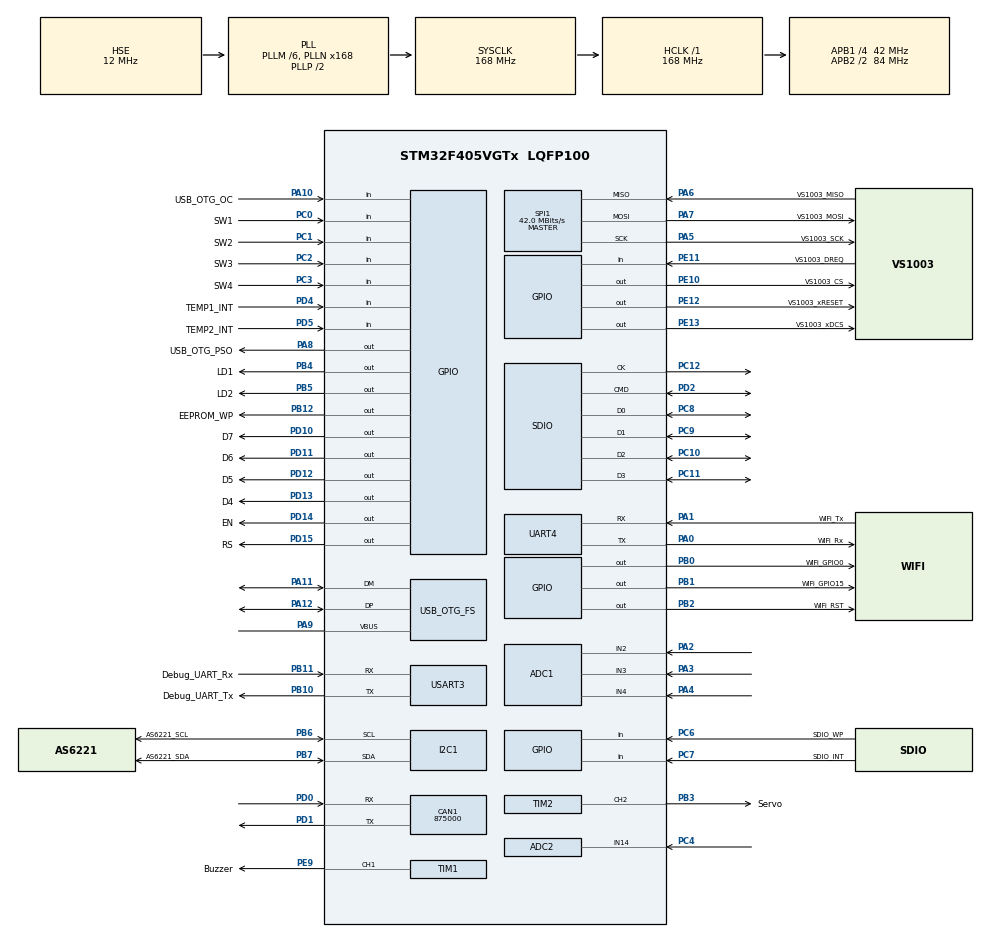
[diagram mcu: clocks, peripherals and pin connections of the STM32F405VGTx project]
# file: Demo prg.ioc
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ADC1.Channel-0\#ChannelRegularConversion=ADC_CHANNEL_2
ADC1.Channel-1\#ChannelRegularConversion=ADC_CHANNEL_3
ADC1.Channel-2\#ChannelRegularConversion=ADC_CHANNEL_4
ADC1.ClockPrescaler=ADC_CLOCK_SYNC_PCLK_DIV4
ADC1.ContinuousConvMode=ENABLE
ADC1.DMAContinuousRequests=ENABLE
ADC1.NbrOfConversion=3
ADC1.NbrOfConversionFlag=1
ADC1.Rank-0\#ChannelRegularConversion=1
ADC1.Rank-1\#ChannelRegularConversion=2
ADC1.Rank-2\#ChannelRegularConversion=3
ADC1.SamplingTime-0\#ChannelRegularConversion=ADC_SAMPLETIME_84CYCLES
ADC1.SamplingTime-1\#ChannelRegularConversion=ADC_SAMPLETIME_84CYCLES
ADC1.SamplingTime-2\#ChannelRegularConversion=ADC_SAMPLETIME_84CYCLES
ADC1.ScanConvMode=ENABLE
ADC1.master=1
ADC2.Channel-0\#ChannelRegularConversion=ADC_CHANNEL_14
ADC2.ClockPrescaler=ADC_CLOCK_SYNC_PCLK_DIV4
ADC2.ContinuousConvMode=ENABLE
ADC2.NbrOfConversionFlag=1
ADC2.Rank-0\#ChannelRegularConversion=1
ADC2.SamplingTime-0\#ChannelRegularConversion=ADC_SAMPLETIME_84CYCLES
ADC2.ScanConvMode=ENABLE
CAN1.CalculateBaudRate=875000
CAN1.CalculateTimeBit=1142
CAN1.CalculateTimeQuantum=380.95238095238096
Dma.ADC1.0.Direction=DMA_PERIPH_TO_MEMORY
Dma.ADC1.0.FIFOMode=DMA_FIFOMODE_DISABLE
Dma.ADC1.0.Instance=DMA2_Stream0
Dma.ADC1.0.MemDataAlignment=DMA_MDATAALIGN_HALFWORD
Dma.ADC1.0.MemInc=DMA_MINC_ENABLE
Dma.ADC1.0.Mode=DMA_CIRCULAR
Dma.ADC1.0.PeriphDataAlignment=DMA_PDATAALIGN_HALFWORD
Dma.ADC1.0.PeriphInc=DMA_PINC_DISABLE
Dma.ADC1.0.Priority=DMA_PRIORITY_LOW
Dma.Request0=ADC1
Dma.Request1=SDIO_TX
Dma.Request2=SDIO_RX
Dma.SDIO_RX.2.Direction=DMA_PERIPH_TO_MEMORY
Dma.SDIO_RX.2.FIFOMode=DMA_FIFOMODE_ENABLE
Dma.SDIO_RX.2.FIFOThreshold=DMA_FIFO_THRESHOLD_FULL
Dma.SDIO_RX.2.Instance=DMA2_Stream6
Dma.SDIO_RX.2.MemBurst=DMA_MBURST_INC4
Dma.SDIO_RX.2.MemDataAlignment=DMA_MDATAALIGN_WORD
Dma.SDIO_RX.2.MemInc=DMA_MINC_ENABLE
Dma.SDIO_RX.2.Mode=DMA_PFCTRL
Dma.SDIO_RX.2.PeriphBurst=DMA_PBURST_INC4
Dma.SDIO_RX.2.PeriphDataAlignment=DMA_PDATAALIGN_WORD
Dma.SDIO_RX.2.PeriphInc=DMA_PINC_DISABLE
Dma.SDIO_RX.2.Priority=DMA_PRIORITY_LOW
Dma.SDIO_TX.1.Direction=DMA_MEMORY_TO_PERIPH
Dma.SDIO_TX.1.FIFOMode=DMA_FIFOMODE_ENABLE
Dma.SDIO_TX.1.FIFOThreshold=DMA_FIFO_THRESHOLD_FULL
Dma.SDIO_TX.1.Instance=DMA2_Stream3
Dma.SDIO_TX.1.MemBurst=DMA_MBURST_INC4
Dma.SDIO_TX.1.MemDataAlignment=DMA_MDATAALIGN_WORD
Dma.SDIO_TX.1.MemInc=DMA_MINC_ENABLE
Dma.SDIO_TX.1.Mode=DMA_PFCTRL
Dma.SDIO_TX.1.PeriphBurst=DMA_PBURST_INC4
Dma.SDIO_TX.1.PeriphDataAlignment=DMA_PDATAALIGN_WORD
Dma.SDIO_TX.1.PeriphInc=DMA_PINC_DISABLE
Dma.SDIO_TX.1.Priority=DMA_PRIORITY_LOW
FATFS.USE_DMA_CODE_SD=1
FATFS._USE_LFN=1
I2C1.I2C_Mode=I2C_Fast
Mcu.Family=STM32F4
Mcu.Name=STM32F405VGTx
Mcu.Package=LQFP100
NVIC.DMA2_Stream0_IRQn=true\:0\:0\:false\:false\:true\:false\:true\:true
NVIC.DMA2_Stream3_IRQn=true\:0\:0\:false\:false\:true\:false\:true\:true
NVIC.DMA2_Stream6_IRQn=true\:0\:0\:false\:false\:true\:false\:true\:true
NVIC.PriorityGroup=NVIC_PRIORITYGROUP_4
NVIC.SDIO_IRQn=true\:0\:0\:false\:false\:true\:true\:true\:true
PA0-WKUP.GPIO_Label=WiFi_Rx
PA0-WKUP.Mode=Asynchronous
PA0-WKUP.Signal=UART4_TX
PA1.GPIO_Label=WiFi_Tx
PA1.Mode=Asynchronous
PA1.Signal=UART4_RX
PA10.GPIO_Label=USB_OTG_OC
PA10.Signal=GPIO_Input
PA11.Mode=Host_Only
PA11.Signal=USB_OTG_FS_DM
PA12.Mode=Host_Only
PA12.Signal=USB_OTG_FS_DP
PA2.Signal=ADCx_IN2
PA3.Signal=ADCx_IN3
PA4.Signal=ADCx_IN4
PA5.GPIO_Label=VS1003_SCK
PA5.Mode=Full_Duplex_Master
PA5.Signal=SPI1_SCK
PA6.GPIO_Label=VS1003_MISO
PA6.Mode=Full_Duplex_Master
PA6.Signal=SPI1_MISO
PA7.GPIO_Label=VS1003_MOSI
PA7.Mode=Full_Duplex_Master
PA7.Signal=SPI1_MOSI
PA8.GPIO_Label=USB_OTG_PSO
PA8.Signal=GPIO_Output
PA9.Mode=Activate_VBUS
PA9.Signal=USB_OTG_FS_VBUS
PB0.GPIO_Label=WiFi_GPIO0
PB0.Signal=GPIO_Output
PB1.GPIO_Label=WiFi_GPIO15
PB1.Signal=GPIO_Output
PB10.GPIO_Label=Debug_UART_Tx
PB10.Mode=Asynchronous
PB10.Signal=USART3_TX
PB11.GPIO_Label=Debug_UART_Rx
PB11.Mode=Asynchronous
PB11.Signal=USART3_RX
PB12.GPIO_Label=EEPROM_WP
PB12.Signal=GPIO_Output
PB2.GPIO_Label=WiFi_RST
PB2.Signal=GPIO_Output
PB3.GPIO_Label=Servo
PB3.Signal=S_TIM2_CH2
PB4.GPIO_Label=LD1
PB4.Signal=GPIO_Output
PB5.GPIO_Label=LD2
PB5.Signal=GPIO_Output
PB6.GPIO_Label=AS6221_SCL
PB6.Mode=I2C
PB6.Signal=I2C1_SCL
PB7.GPIO_Label=AS6221_SDA
PB7.Mode=I2C
PB7.Signal=I2C1_SDA
PC0.GPIO_Label=SW1
PC0.Signal=GPIO_Input
PC1.GPIO_Label=SW2
PC1.Signal=GPIO_Input
PC10.Mode=SD_4_bits_Wide_bus
PC10.Signal=SDIO_D2
PC11.Mode=SD_4_bits_Wide_bus
PC11.Signal=SDIO_D3
PC12.Mode=SD_4_bits_Wide_bus
PC12.Signal=SDIO_CK
PC2.GPIO_Label=SW3
PC2.Signal=GPIO_Input
PC3.GPIO_Label=SW4
PC3.Signal=GPIO_Input
PC4.Signal=ADCx_IN14
PC6.GPIO_Label=SDIO_WP
PC6.Signal=GPIO_Input
PC7.GPIO_Label=SDIO_INT
PC7.Signal=GPIO_Input
PC8.Mode=SD_4_bits_Wide_bus
PC8.Signal=SDIO_D0
PC9.Mode=SD_4_bits_Wide_bus
PC9.Signal=SDIO_D1
PD0.Mode=CAN_Activate
PD0.Signal=CAN1_RX
PD1.Mode=CAN_Activate
PD1.Signal=CAN1_TX
PD10.GPIO_Label=D7
PD10.Signal=GPIO_Output
PD11.GPIO_Label=D6
PD11.Signal=GPIO_Output
PD12.GPIO_Label=D5
PD12.Signal=GPIO_Output
PD13.GPIO_Label=D4
PD13.Signal=GPIO_Output
PD14.GPIO_Label=EN
PD14.Signal=GPIO_Output
PD15.GPIO_Label=RS
PD15.Signal=GPIO_Output
PD2.Mode=SD_4_bits_Wide_bus
PD2.Signal=SDIO_CMD
PD4.GPIO_Label=TEMP1_INT
PD4.Signal=GPIO_Input
PD5.GPIO_Label=TEMP2_INT
PD5.Signal=GPIO_Input
PE10.GPIO_Label=VS1003_CS
PE10.Signal=GPIO_Output
PE11.GPIO_Label=VS1003_DREQ
PE11.Signal=GPIO_Input
PE12.GPIO_Label=VS1003_xRESET
PE12.Signal=GPIO_Output
PE13.GPIO_Label=VS1003_xDCS
PE13.Signal=GPIO_Output
PE9.GPIO_Label=Buzzer
PE9.Signal=S_TIM1_CH1
PH0-OSC_IN.Mode=HSE-External-Oscillator
PH0-OSC_IN.Signal=RCC_OSC_IN
PH1-OSC_OUT.Mode=HSE-External-Oscillator
PH1-OSC_OUT.Signal=RCC_OSC_OUT
ProjectManager.HeapSize=0x200
ProjectManager.StackSize=0x400
ProjectManager.TargetToolchain=STM32CubeIDE
RCC.48MHZClocksFreq_Value=48000000
RCC.AHBFreq_Value=168000000
RCC.APB1CLKDivider=RCC_HCLK_DIV4
RCC.APB1Freq_Value=42000000
RCC.APB1TimFreq_Value=84000000
RCC.APB2CLKDivider=RCC_HCLK_DIV2
RCC.APB2Freq_Value=84000000
RCC.APB2TimFreq_Value=168000000
RCC.CortexFreq_Value=168000000
RCC.HCLKFreq_Value=168000000
RCC.HSE_VALUE=12000000
RCC.HSI_VALUE=16000000
RCC.LSE_VALUE=32768
RCC.PLLM=6
RCC.PLLN=168
RCC.PLLQ=7
RCC.SYSCLKFreq_VALUE=168000000
RCC.SYSCLKSource=RCC_SYSCLKSOURCE_PLLCLK
RCC.VCOOutputFreq_Value=336000000
SH.ADCx_IN14.0=ADC2_IN14,IN14
SH.ADCx_IN2.0=ADC1_IN2,IN2
SH.ADCx_IN3.0=ADC1_IN3,IN3
SH.ADCx_IN4.0=ADC1_IN4,IN4
SH.S_TIM1_CH1.0=TIM1_CH1,PWM Generation1 CH1
SH.S_TIM2_CH2.0=TIM2_CH2,PWM Generation2 CH2
SPI1.CalculateBaudRate=42.0 MBits/s
SPI1.Direction=SPI_DIRECTION_2LINES
SPI1.Mode=SPI_MODE_MASTER
SPI1.VirtualType=VM_MASTER
TIM1.Channel-PWM\ Generation1\ CH1=TIM_CHANNEL_1
TIM1.Period=9
TIM1.Prescaler=8399
TIM1.Pulse-PWM\ Generation1\ CH1=5
TIM2.Channel-PWM\ Generation2\ CH2=TIM_CHANNEL_2
TIM2.Period=19999
TIM2.Prescaler=167
TIM2.Pulse-PWM\ Generation2\ CH2=1500
TIM4.Prescaler=83
UART4.VirtualMode=Asynchronous
USART3.VirtualMode=VM_ASYNC
USB_OTG_FS.VirtualMode=Host_Only
USB_OTG_FS.phy_itface=HCD_PHY_EMBEDDED
VP_FATFS_VS_SDIO.Mode=SDIO
VP_TIM1_VS_ClockSourceINT.Mode=Internal
VP_TIM2_VS_ClockSourceINT.Mode=Internal
VP_TIM4_VS_ClockSourceINT.Mode=Internal
board=custom

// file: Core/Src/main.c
/* USER CODE BEGIN Header */
/**
  ******************************************************************************
  * @file           : main.c
  * @brief          : Main program body
  ******************************************************************************
  * @attention
  *
  * Copyright (c) 2025 STMicroelectronics.
  * All rights reserved.
  *
  * This software is licensed under terms that can be found in the LICENSE file
  * in the root directory of this software component.
  * If no LICENSE file comes with this software, it is provided AS-IS.
  *
  ******************************************************************************
  */
/* USER CODE END Header */
#include "main.h"
#include "adc.h"
#include "can.h"
#include "dma.h"
#include "fatfs.h"
#include "i2c.h"
#include "sdio.h"
#include "spi.h"
#include "tim.h"
#include "usart.h"
#include "usb_otg.h"
#include "gpio.h"

/* USER CODE BEGIN Includes */
#include "app.h"

/* USER CODE END Includes */

/* USER CODE BEGIN PV */
volatile uint16_t adc1_dma_buf[3];

/* USER CODE END PV */

void SystemClock_Config(void);

int main(void)
{

  /* MCU Configuration--------------------------------------------------------*/

  /* Reset of all peripherals, Initializes the Flash interface and the Systick. */
  HAL_Init();

  /* Configure the system clock */
  SystemClock_Config();

  /* Initialize all configured peripherals */
  MX_GPIO_Init();
  MX_DMA_Init();
  MX_ADC1_Init();
  MX_ADC2_Init();
  MX_CAN1_Init();
  MX_I2C1_Init();
  MX_SDIO_SD_Init();
  MX_SPI1_Init();
  MX_TIM1_Init();
  MX_TIM2_Init();
  MX_UART4_Init();
  MX_USART3_UART_Init();
  MX_FATFS_Init();
  MX_TIM4_Init();
  MX_USB_OTG_FS_HCD_Init();
  /* USER CODE BEGIN 2 */
  // ADC1 DMA 시작 (프로젝트 버퍼명에 맞게)
  HAL_ADC_Start_DMA(&hadc1, (uint32_t*)adc1_dma_buf, 3);

  // 서보 PWM 스타트
  HAL_TIM_PWM_Start(&htim2, TIM_CHANNEL_2);

  App_Init();

  /* USER CODE END 2 */

  /* Infinite loop */
  /* USER CODE BEGIN WHILE */
  while (1)
  {
	  App_Task();
    /* USER CODE END WHILE */

  }
}

void SystemClock_Config(void)
{
  RCC_OscInitTypeDef RCC_OscInitStruct = {0};
  RCC_ClkInitTypeDef RCC_ClkInitStruct = {0};

  /** Configure the main internal regulator output voltage
  */
  __HAL_RCC_PWR_CLK_ENABLE();
  __HAL_PWR_VOLTAGESCALING_CONFIG(PWR_REGULATOR_VOLTAGE_SCALE1);

  /** Initializes the RCC Oscillators according to the specified parameters
  * in the RCC_OscInitTypeDef structure.
  */
  RCC_OscInitStruct.OscillatorType = RCC_OSCILLATORTYPE_HSE;
  RCC_OscInitStruct.HSEState = RCC_HSE_ON;
  RCC_OscInitStruct.PLL.PLLState = RCC_PLL_ON;
  RCC_OscInitStruct.PLL.PLLSource = RCC_PLLSOURCE_HSE;
  RCC_OscInitStruct.PLL.PLLM = 6;
  RCC_OscInitStruct.PLL.PLLN = 168;
  RCC_OscInitStruct.PLL.PLLP = RCC_PLLP_DIV2;
  RCC_OscInitStruct.PLL.PLLQ = 7;
  if (HAL_RCC_OscConfig(&RCC_OscInitStruct) != HAL_OK)
  {
    Error_Handler();
  }

  /** Initializes the CPU, AHB and APB buses clocks
  */
  RCC_ClkInitStruct.ClockType = RCC_CLOCKTYPE_HCLK|RCC_CLOCKTYPE_SYSCLK
                              |RCC_CLOCKTYPE_PCLK1|RCC_CLOCKTYPE_PCLK2;
  RCC_ClkInitStruct.SYSCLKSource = RCC_SYSCLKSOURCE_PLLCLK;
  RCC_ClkInitStruct.AHBCLKDivider = RCC_SYSCLK_DIV1;
  RCC_ClkInitStruct.APB1CLKDivider = RCC_HCLK_DIV4;
  RCC_ClkInitStruct.APB2CLKDivider = RCC_HCLK_DIV2;

  if (HAL_RCC_ClockConfig(&RCC_ClkInitStruct, FLASH_LATENCY_5) != HAL_OK)
  {
    Error_Handler();
  }
}

void Error_Handler(void)
{
  __disable_irq();
  while (1)
  {
  }
}
